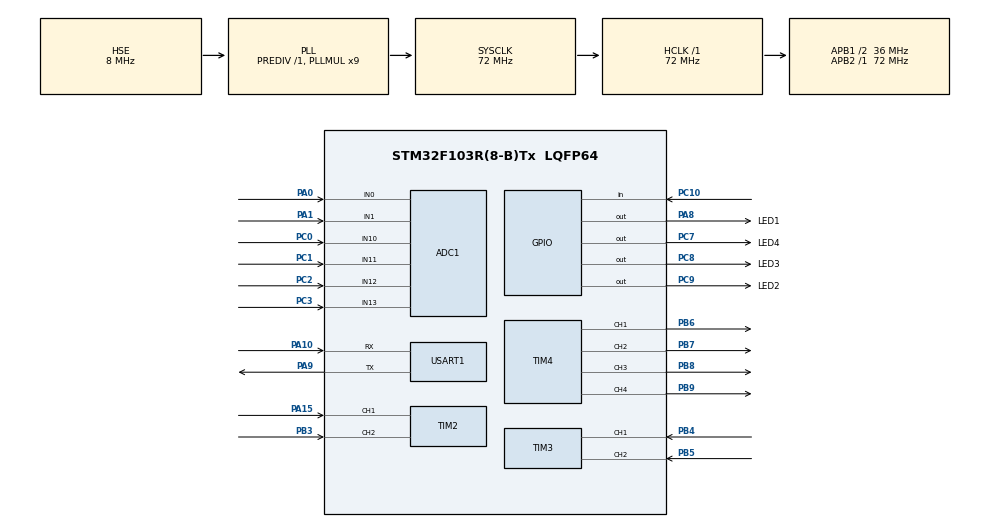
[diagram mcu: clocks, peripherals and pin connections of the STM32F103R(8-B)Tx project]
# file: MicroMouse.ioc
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ADC1.Channel-0\#ChannelRegularConversion=ADC_CHANNEL_10
ADC1.NbrOfConversionFlag=1
ADC1.Rank-0\#ChannelRegularConversion=1
ADC1.SamplingTime-0\#ChannelRegularConversion=ADC_SAMPLETIME_1CYCLE_5
ADC1.master=1
Mcu.Family=STM32F1
Mcu.Name=STM32F103R(8-B)Tx
Mcu.Package=LQFP64
NVIC.PriorityGroup=NVIC_PRIORITYGROUP_4
PA0-WKUP.Signal=ADCx_IN0
PA1.Signal=ADCx_IN1
PA10.Mode=Asynchronous
PA10.Signal=USART1_RX
PA13.Mode=Serial_Wire
PA13.Signal=SYS_JTMS-SWDIO
PA14.Mode=Serial_Wire
PA14.Signal=SYS_JTCK-SWCLK
PA15.Signal=S_TIM2_CH1_ETR
PA8.GPIO_Label=LED1
PA8.Signal=GPIO_Output
PA9.Mode=Asynchronous
PA9.Signal=USART1_TX
PB3.Signal=S_TIM2_CH2
PB4.Signal=S_TIM3_CH1
PB5.Signal=S_TIM3_CH2
PB6.Signal=S_TIM4_CH1
PB7.Signal=S_TIM4_CH2
PB8.Signal=S_TIM4_CH3
PB9.Signal=S_TIM4_CH4
PC0.Signal=ADCx_IN10
PC1.Signal=ADCx_IN11
PC10.Signal=GPIO_Input
PC2.Signal=ADCx_IN12
PC3.Signal=ADCx_IN13
PC7.GPIO_Label=LED4
PC7.Signal=GPIO_Output
PC8.GPIO_Label=LED3
PC8.Signal=GPIO_Output
PC9.GPIO_Label=LED2
PC9.Signal=GPIO_Output
PD0-OSC_IN.Mode=HSE-External-Oscillator
PD0-OSC_IN.Signal=RCC_OSC_IN
PD1-OSC_OUT.Mode=HSE-External-Oscillator
PD1-OSC_OUT.Signal=RCC_OSC_OUT
ProjectManager.HeapSize=0x200
ProjectManager.StackSize=0x400
ProjectManager.TargetToolchain=STM32CubeIDE
RCC.ADCPresc=RCC_ADCPCLK2_DIV6
RCC.AHBFreq_Value=72000000
RCC.APB1CLKDivider=RCC_HCLK_DIV2
RCC.APB1Freq_Value=36000000
RCC.APB1TimFreq_Value=72000000
RCC.APB2Freq_Value=72000000
RCC.APB2TimFreq_Value=72000000
RCC.HCLKFreq_Value=72000000
RCC.HSICalibrationValue=8
RCC.PLLMUL=RCC_PLL_MUL9
RCC.PLLSourceVirtual=RCC_PLLSOURCE_HSE
RCC.SYSCLKFreq_VALUE=72000000
RCC.SYSCLKSource=RCC_SYSCLKSOURCE_PLLCLK
RCC.USBFreq_Value=72000000
SH.ADCx_IN0.0=ADC1_IN0,IN0
SH.ADCx_IN1.0=ADC1_IN1,IN1
SH.ADCx_IN10.0=ADC1_IN10,IN10
SH.ADCx_IN11.0=ADC1_IN11,IN11
SH.ADCx_IN12.0=ADC1_IN12,IN12
SH.ADCx_IN13.0=ADC1_IN13,IN13
SH.S_TIM2_CH1_ETR.0=TIM2_CH1,Encoder_Interface
SH.S_TIM2_CH2.0=TIM2_CH2,Encoder_Interface
SH.S_TIM3_CH1.0=TIM3_CH1,Encoder_Interface
SH.S_TIM3_CH2.0=TIM3_CH2,Encoder_Interface
SH.S_TIM4_CH1.0=TIM4_CH1,PWM Generation1 CH1
SH.S_TIM4_CH2.0=TIM4_CH2,PWM Generation2 CH2
SH.S_TIM4_CH3.0=TIM4_CH3,PWM Generation3 CH3
SH.S_TIM4_CH4.0=TIM4_CH4,PWM Generation4 CH4
TIM2.Channel-Input_Capture1_from_TI1=TIM_CHANNEL_1
TIM2.Channel-Input_Capture2_from_TI2=TIM_CHANNEL_2
TIM2.EncoderMode=TIM_ENCODERMODE_TI12
TIM3.Channel-Input_Capture1_from_TI1=TIM_CHANNEL_1
TIM3.Channel-Input_Capture2_from_TI2=TIM_CHANNEL_2
TIM3.EncoderMode=TIM_ENCODERMODE_TI12
TIM4.Channel-PWM\ Generation1\ CH1=TIM_CHANNEL_1
TIM4.Channel-PWM\ Generation2\ CH2=TIM_CHANNEL_2
TIM4.Channel-PWM\ Generation3\ CH3=TIM_CHANNEL_3
TIM4.Channel-PWM\ Generation4\ CH4=TIM_CHANNEL_4
USART1.VirtualMode=VM_ASYNC
VP_TIM4_VS_ClockSourceINT.Mode=Internal
board=custom

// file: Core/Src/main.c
/* USER CODE BEGIN Header */
/**
  ******************************************************************************
  * @file           : main.c
  * @brief          : Main program body
  ******************************************************************************
  * @attention
  *
  * Copyright (c) 2025 STMicroelectronics.
  * All rights reserved.
  *
  * This software is licensed under terms that can be found in the LICENSE file
  * in the root directory of this software component.
  * If no LICENSE file comes with this software, it is provided AS-IS.
  *
  ******************************************************************************
  */
/* USER CODE END Header */
#include "main.h"
#include "adc.h"
#include "tim.h"
#include "usart.h"
#include "gpio.h"

/* USER CODE BEGIN Includes */
#include "stdio.h"
/* USER CODE END Includes */

void SystemClock_Config(void);

int main(void)
{

  /* MCU Configuration--------------------------------------------------------*/

  /* Reset of all peripherals, Initializes the Flash interface and the Systick. */
  HAL_Init();

  /* Configure the system clock */
  SystemClock_Config();

  /* Initialize all configured peripherals */
  MX_GPIO_Init();
  MX_ADC1_Init();
  MX_TIM2_Init();
  MX_TIM3_Init();
  MX_TIM4_Init();
  MX_USART1_UART_Init();

  /* Infinite loop */
  while (1)
  {

    /* USER CODE BEGIN 3 */
    HAL_GPIO_WritePin(LED1_GPIO_Port, LED1_Pin, GPIO_PIN_RESET);
    HAL_GPIO_WritePin(GPIOC, LED2_Pin|LED3_Pin|LED4_Pin, GPIO_PIN_SET);
    printf("hello world!\r\n");
    HAL_Delay(1000);
  }
  /* USER CODE END 3 */
}

void SystemClock_Config(void)
{
  RCC_OscInitTypeDef RCC_OscInitStruct = {0};
  RCC_ClkInitTypeDef RCC_ClkInitStruct = {0};
  RCC_PeriphCLKInitTypeDef PeriphClkInit = {0};

  /** Initializes the RCC Oscillators according to the specified parameters
  * in the RCC_OscInitTypeDef structure.
  */
  RCC_OscInitStruct.OscillatorType = RCC_OSCILLATORTYPE_HSE;
  RCC_OscInitStruct.HSEState = RCC_HSE_ON;
  RCC_OscInitStruct.HSEPredivValue = RCC_HSE_PREDIV_DIV1;
  RCC_OscInitStruct.HSIState = RCC_HSI_ON;
  RCC_OscInitStruct.PLL.PLLState = RCC_PLL_ON;
  RCC_OscInitStruct.PLL.PLLSource = RCC_PLLSOURCE_HSE;
  RCC_OscInitStruct.PLL.PLLMUL = RCC_PLL_MUL9;
  if (HAL_RCC_OscConfig(&RCC_OscInitStruct) != HAL_OK)
  {
    Error_Handler();
  }

  /** Initializes the CPU, AHB and APB buses clocks
  */
  RCC_ClkInitStruct.ClockType = RCC_CLOCKTYPE_HCLK|RCC_CLOCKTYPE_SYSCLK
                              |RCC_CLOCKTYPE_PCLK1|RCC_CLOCKTYPE_PCLK2;
  RCC_ClkInitStruct.SYSCLKSource = RCC_SYSCLKSOURCE_PLLCLK;
  RCC_ClkInitStruct.AHBCLKDivider = RCC_SYSCLK_DIV1;
  RCC_ClkInitStruct.APB1CLKDivider = RCC_HCLK_DIV2;
  RCC_ClkInitStruct.APB2CLKDivider = RCC_HCLK_DIV1;

  if (HAL_RCC_ClockConfig(&RCC_ClkInitStruct, FLASH_LATENCY_2) != HAL_OK)
  {
    Error_Handler();
  }
  PeriphClkInit.PeriphClockSelection = RCC_PERIPHCLK_ADC;
  PeriphClkInit.AdcClockSelection = RCC_ADCPCLK2_DIV6;
  if (HAL_RCCEx_PeriphCLKConfig(&PeriphClkInit) != HAL_OK)
  {
    Error_Handler();
  }
}

/* USER CODE BEGIN 4 */
#ifdef __GNUC__
#define PUTCHAR_PROTOTYPE int __io_putchar(int ch)
#else
#define PUTCHAR_PROTOTYPE int fputc(int ch, FILE *f)
#endif

PUTCHAR_PROTOTYPE {
  HAL_UART_Transmit(&huart1, (uint8_t *) &ch, 1, 100);
  return ch;
}
/* USER CODE END 4 */

void Error_Handler(void)
{
  __disable_irq();
  while (1)
  {
  }
}
